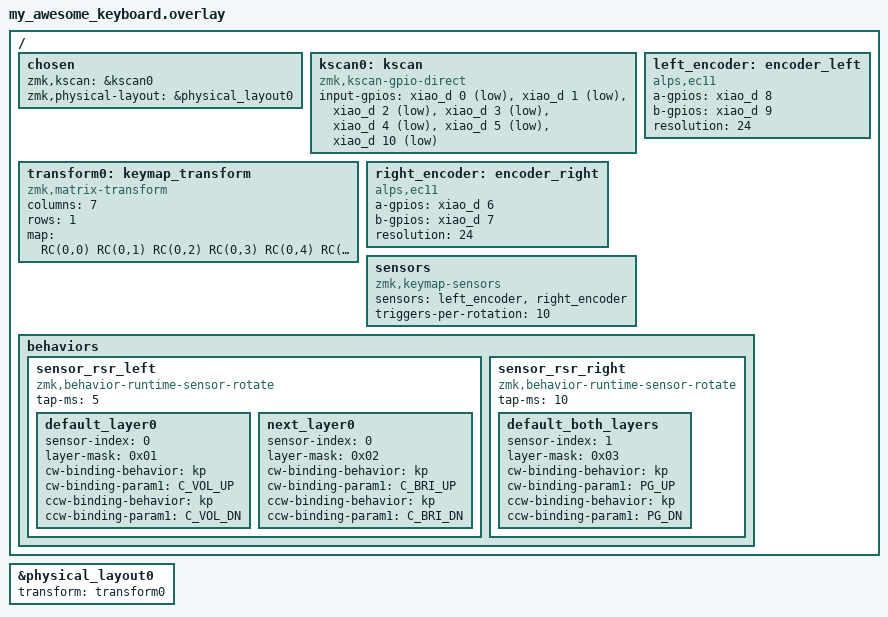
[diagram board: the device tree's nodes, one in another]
/*
* Copyright (c) 2025 The ZMK Contributors
*
* SPDX-License-Identifier: MIT
*/
#include "my_awesome_keyboard-layouts.dtsi"
#include <behaviors.dtsi>
#include <dt-bindings/zmk/matrix_transform.h>

&physical_layout0 {
	transform = <&transform0>;
};

/ {
	chosen {
		zmk,kscan = &kscan0;
		zmk,physical-layout = &physical_layout0;
	};
	
	kscan0: kscan {
		compatible = "zmk,kscan-gpio-direct";
		input-gpios
		= <&xiao_d 0 (GPIO_ACTIVE_LOW | GPIO_PULL_UP)>
		, <&xiao_d 1 (GPIO_ACTIVE_LOW | GPIO_PULL_UP)>
		, <&xiao_d 2 (GPIO_ACTIVE_LOW | GPIO_PULL_UP)>
		, <&xiao_d 3 (GPIO_ACTIVE_LOW | GPIO_PULL_UP)>
		, <&xiao_d 4 (GPIO_ACTIVE_LOW | GPIO_PULL_UP)>
		, <&xiao_d 5 (GPIO_ACTIVE_LOW | GPIO_PULL_UP)>
		, <&xiao_d 10 (GPIO_ACTIVE_LOW | GPIO_PULL_UP)>
		;
	};
	
	transform0: keymap_transform {
		compatible = "zmk,matrix-transform";
		columns = <7>;
		rows = <1>;
		map = <
		RC(0,0)  RC(0,1)  RC(0,2)  RC(0,3)  RC(0,4)  RC(0,5)  RC(0,6)
		>;
	};
	
	right_encoder: encoder_right {
		compatible = "alps,ec11";
		a-gpios = <&xiao_d 6 (GPIO_ACTIVE_HIGH | GPIO_PULL_UP)>;
		b-gpios = <&xiao_d 7 (GPIO_ACTIVE_HIGH | GPIO_PULL_UP)>;
		resolution = <24>;
		status = "okay";
	};
	
	left_encoder: encoder_left {
		compatible = "alps,ec11";
		a-gpios = <&xiao_d 8 (GPIO_ACTIVE_HIGH | GPIO_PULL_UP)>;
		b-gpios = <&xiao_d 9 (GPIO_ACTIVE_HIGH | GPIO_PULL_UP)>;
		resolution = <24>;
		status = "okay";
	};
	
	sensors: sensors {
		compatible = "zmk,keymap-sensors";
		sensors = <&left_encoder &right_encoder>;
		triggers-per-rotation = <10>;
	};
	
	behaviors {
		sensor_rsr_left: sensor_rsr_left {
			compatible = "zmk,behavior-runtime-sensor-rotate";
			#sensor-binding-cells = <0>;
			tap-ms = <5>;
			
			// Default binding for sensor 0, layer 0 (default layer)
			default_layer0 {
				sensor-index = <0>;
				layer-mask = <0x01>;// bit 0 = layer 0
				cw-binding-behavior = "kp";
				cw-binding-param1 = <C_VOL_UP>;
				ccw-binding-behavior = "kp";
				ccw-binding-param1 = <C_VOL_DN>;
			};
			
			// Default binding for sensor 0, layer 1 (next layer)
			next_layer0 {
				sensor-index = <0>;
				layer-mask = <0x02>;// bit 1 = layer 1
				cw-binding-behavior = "kp";
				cw-binding-param1 = <C_BRI_UP>;
				ccw-binding-behavior = "kp";
				ccw-binding-param1 = <C_BRI_DN>;
			};
		};
		
		sensor_rsr_right: sensor_rsr_right {
			compatible = "zmk,behavior-runtime-sensor-rotate";
			#sensor-binding-cells = <0>;
			tap-ms = <10>;
			
			// Default binding for sensor 1, layers 0 and 1
			default_both_layers {
				sensor-index = <1>;
				layer-mask = <0x03>;// bits 0-1 = layers 0-1
				cw-binding-behavior = "kp";
				cw-binding-param1 = <PG_UP>;
				ccw-binding-behavior = "kp";
				ccw-binding-param1 = <PG_DN>;
			};
		};
	};
};
